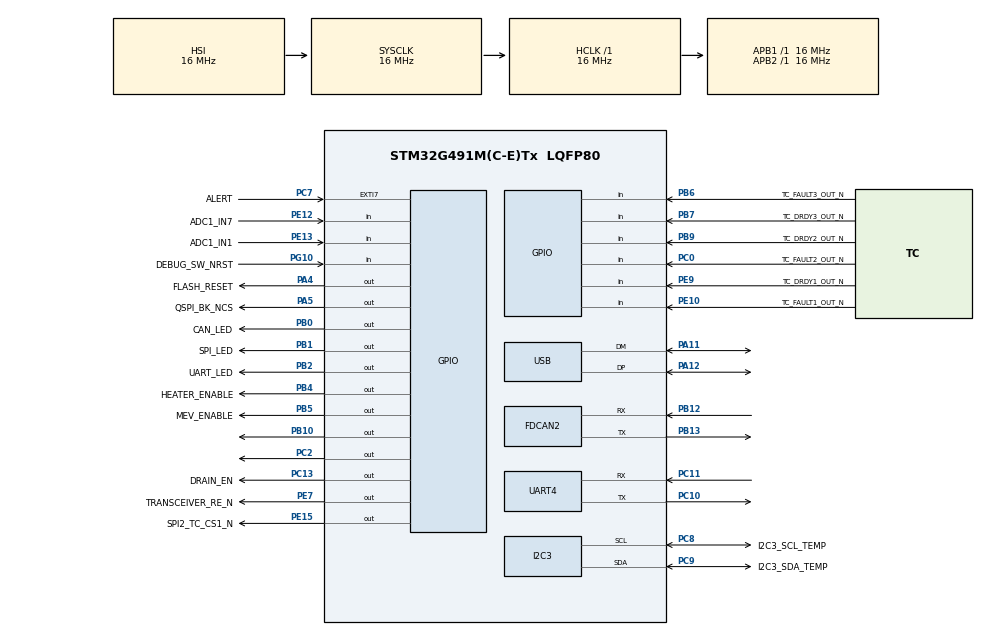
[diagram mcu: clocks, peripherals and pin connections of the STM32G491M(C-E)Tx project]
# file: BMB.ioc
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FDCAN2.CalculateBaudRateNominal=200000
FDCAN2.CalculateTimeBitNominal=5000
FDCAN2.CalculateTimeQuantumNominal=1000.0
FREERTOS.Tasks01=defaultTask,0,192,StartDefaultTask,Default,NULL,Dynamic,NULL,NULL
FREERTOS.configMINIMAL_STACK_SIZE=192
FREERTOS.configTOTAL_HEAP_SIZE=64000
FREERTOS.configUSE_NEWLIB_REENTRANT=1
FREERTOS.configUSE_TIMERS=1
Mcu.Family=STM32G4
Mcu.Name=STM32G491M(C-E)Tx
Mcu.Package=LQFP80
NVIC.EXTI9_5_IRQn=true\:5\:0\:false\:false\:true\:true\:true\:true\:true
NVIC.I2C3_EV_IRQn=true\:5\:0\:false\:false\:true\:true\:true\:true\:true
NVIC.PriorityGroup=NVIC_PRIORITYGROUP_4
NVIC.TIM2_IRQn=true\:15\:0\:false\:false\:true\:false\:false\:true\:true
NVIC.TimeBase=TIM2_IRQn
NVIC.TimeBaseIP=TIM2
NVIC.UART4_IRQn=true\:5\:0\:false\:false\:true\:true\:true\:true\:true
PA11.Mode=Device
PA11.Signal=USB_DM
PA12.Mode=Device
PA12.Signal=USB_DP
PA13.Mode=JTAG_4_pins
PA13.Signal=SYS_JTMS-SWDIO
PA14.Mode=JTAG_4_pins
PA14.Signal=SYS_JTCK-SWCLK
PA15.Mode=JTAG_4_pins
PA15.Signal=SYS_JTDI
PA4.GPIO_Label=FLASH_RESET
PA4.Signal=GPIO_Output
PA5.GPIO_Label=QSPI_BK_NCS
PA5.Signal=GPIO_Output
PB0.GPIO_Label=CAN_LED
PB0.Signal=GPIO_Output
PB1.GPIO_Label=SPI_LED
PB1.Signal=GPIO_Output
PB10.Signal=GPIO_Output
PB12.Mode=FDCAN_Activate
PB12.Signal=FDCAN2_RX
PB13.Mode=FDCAN_Activate
PB13.Signal=FDCAN2_TX
PB2.GPIO_Label=UART_LED
PB2.Signal=GPIO_Output
PB3.Mode=JTAG_4_pins
PB3.Signal=SYS_JTDO-SWO
PB4.GPIO_Label=HEATER_ENABLE
PB4.Signal=GPIO_Output
PB5.GPIO_Label=MEV_ENABLE
PB5.Signal=GPIO_Output
PB6.GPIO_Label=TC_FAULT3_OUT_N
PB6.Signal=GPIO_Input
PB7.GPIO_Label=TC_DRDY3_OUT_N
PB7.Signal=GPIO_Input
PB9.GPIO_Label=TC_DRDY2_OUT_N
PB9.Signal=GPIO_Input
PC0.GPIO_Label=TC_FAULT2_OUT_N
PC0.Signal=GPIO_Input
PC10.Mode=Asynchronous
PC10.Signal=UART4_TX
PC11.Mode=Asynchronous
PC11.Signal=UART4_RX
PC13.GPIO_Label=DRAIN_EN
PC13.Signal=GPIO_Output
PC2.Signal=GPIO_Output
PC7.GPIO_Label=ALERT
PC7.Signal=GPXTI7
PC8.GPIO_Label=I2C3_SCL_TEMP
PC8.Mode=I2C
PC8.Signal=I2C3_SCL
PC9.GPIO_Label=I2C3_SDA_TEMP
PC9.Mode=I2C
PC9.Signal=I2C3_SDA
PE10.GPIO_Label=TC_FAULT1_OUT_N
PE10.Signal=GPIO_Input
PE12.GPIO_Label=ADC1_IN7
PE12.Signal=GPIO_Input
PE13.GPIO_Label=ADC1_IN1
PE13.Signal=GPIO_Input
PE15.GPIO_Label=SPI2_TC_CS1_N
PE15.Signal=GPIO_Output
PE7.GPIO_Label=TRANSCEIVER_RE_N
PE7.Signal=GPIO_Output
PE9.GPIO_Label=TC_DRDY1_OUT_N
PE9.Signal=GPIO_Input
PF0-OSC_IN.Mode=HSE-External-Oscillator
PF0-OSC_IN.Signal=RCC_OSC_IN
PF1-OSC_OUT.Mode=HSE-External-Oscillator
PF1-OSC_OUT.Signal=RCC_OSC_OUT
PG10-NRST.GPIO_Label=DEBUG_SW_NRST
PG10-NRST.Signal=GPIO_Input
ProjectManager.HeapSize=0x200
ProjectManager.StackSize=0x400
ProjectManager.TargetToolchain=STM32CubeIDE
RCC.AHBFreq_Value=16000000
RCC.APB1Freq_Value=16000000
RCC.APB1TimFreq_Value=16000000
RCC.APB2Freq_Value=16000000
RCC.APB2TimFreq_Value=16000000
RCC.CortexFreq_Value=16000000
RCC.EXTERNAL_CLOCK_VALUE=12288000
RCC.HCLKFreq_Value=16000000
RCC.HSE_VALUE=8000000
RCC.HSI48_VALUE=48000000
RCC.HSI_VALUE=16000000
RCC.LSE_VALUE=32768
RCC.SYSCLKFreq_VALUE=16000000
RCC.USBFreq_Value=48000000
RCC.VCOOutputFreq_Value=128000000
VP_CRC_VS_CRC.Mode=CRC_Activate
VP_FREERTOS_VS_CMSIS_V1.Mode=CMSIS_V1
VP_SYS_VS_DBSignals.Mode=DisableDeadBatterySignals
VP_SYS_VS_tim2.Mode=TIM2
board=custom

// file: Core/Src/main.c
/* USER CODE BEGIN Header */
/**
  ******************************************************************************
  * @file           : main.c
  * @brief          : Main program body
  ******************************************************************************
  * @attention
  *
  * Copyright (c) 2026 STMicroelectronics.
  * All rights reserved.
  *
  * This software is licensed under terms that can be found in the LICENSE file
  * in the root directory of this software component.
  * If no LICENSE file comes with this software, it is provided AS-IS.
  *
  ******************************************************************************
  */
/* USER CODE END Header */
#include "main.h"
#include "cmsis_os.h"

/* USER CODE BEGIN Includes */

//#define USE_FULL_LL_DRIVER
/* USER CODE END Includes */

CRC_HandleTypeDef hcrc;

FDCAN_HandleTypeDef hfdcan2;

I2C_HandleTypeDef hi2c3;

UART_HandleTypeDef huart4;

PCD_HandleTypeDef hpcd_USB_FS;

osThreadId defaultTaskHandle;

void SystemClock_Config(void);
static void MX_GPIO_Init(void);
static void MX_CRC_Init(void);
static void MX_I2C3_Init(void);
static void MX_FDCAN2_Init(void);
static void MX_UART4_Init(void);
static void MX_USB_PCD_Init(void);
void StartDefaultTask(void const * argument);

/* USER CODE BEGIN PFP */
void BQ76942_NotifyAlertInterrupt(void);
void run_interface(void);

/* USER CODE END PFP */

int main(void)
{

  /* MCU Configuration--------------------------------------------------------*/

  /* Reset of all peripherals, Initializes the Flash interface and the Systick. */
  HAL_Init();

  /* Configure the system clock */
  SystemClock_Config();

  /* Initialize all configured peripherals */
  MX_GPIO_Init();
  MX_CRC_Init();
  MX_I2C3_Init();
  MX_FDCAN2_Init();
  MX_UART4_Init();
  MX_USB_PCD_Init();
  /* USER CODE BEGIN 2 */
  __enable_irq();

  run_interface();
  #if 0
  /* USER CODE END 2 */

  /* Create the thread(s) */
  /* definition and creation of defaultTask */
  osThreadDef(defaultTask, StartDefaultTask, osPriorityNormal, 0, 192);
  defaultTaskHandle = osThreadCreate(osThread(defaultTask), NULL);

  /* Start scheduler */
  osKernelStart();

  /* We should never get here as control is now taken by the scheduler */
  /* Infinite loop */
  while (1)
  {

    /* USER CODE BEGIN 3 */
  }

#endif
  /* USER CODE END 3 */
}

void SystemClock_Config(void)
{
  RCC_OscInitTypeDef RCC_OscInitStruct = {0};
  RCC_ClkInitTypeDef RCC_ClkInitStruct = {0};

  /** Configure the main internal regulator output voltage
  */
  HAL_PWREx_ControlVoltageScaling(PWR_REGULATOR_VOLTAGE_SCALE1);

  /** Initializes the RCC Oscillators according to the specified parameters
  * in the RCC_OscInitTypeDef structure.
  */
  RCC_OscInitStruct.OscillatorType = RCC_OSCILLATORTYPE_HSI|RCC_OSCILLATORTYPE_HSI48;
  RCC_OscInitStruct.HSIState = RCC_HSI_ON;
  RCC_OscInitStruct.HSICalibrationValue = RCC_HSICALIBRATION_DEFAULT;
  RCC_OscInitStruct.HSI48State = RCC_HSI48_ON;
  RCC_OscInitStruct.PLL.PLLState = RCC_PLL_NONE;
  if (HAL_RCC_OscConfig(&RCC_OscInitStruct) != HAL_OK)
  {
    Error_Handler();
  }

  /** Initializes the CPU, AHB and APB buses clocks
  */
  RCC_ClkInitStruct.ClockType = RCC_CLOCKTYPE_HCLK|RCC_CLOCKTYPE_SYSCLK
                              |RCC_CLOCKTYPE_PCLK1|RCC_CLOCKTYPE_PCLK2;
  RCC_ClkInitStruct.SYSCLKSource = RCC_SYSCLKSOURCE_HSI;
  RCC_ClkInitStruct.AHBCLKDivider = RCC_SYSCLK_DIV1;
  RCC_ClkInitStruct.APB1CLKDivider = RCC_HCLK_DIV1;
  RCC_ClkInitStruct.APB2CLKDivider = RCC_HCLK_DIV1;

  if (HAL_RCC_ClockConfig(&RCC_ClkInitStruct, FLASH_LATENCY_0) != HAL_OK)
  {
    Error_Handler();
  }
}

static void MX_CRC_Init(void)
{

  hcrc.Instance = CRC;
  hcrc.Init.DefaultPolynomialUse = DEFAULT_POLYNOMIAL_ENABLE;
  hcrc.Init.DefaultInitValueUse = DEFAULT_INIT_VALUE_ENABLE;
  hcrc.Init.InputDataInversionMode = CRC_INPUTDATA_INVERSION_NONE;
  hcrc.Init.OutputDataInversionMode = CRC_OUTPUTDATA_INVERSION_DISABLE;
  hcrc.InputDataFormat = CRC_INPUTDATA_FORMAT_BYTES;
  if (HAL_CRC_Init(&hcrc) != HAL_OK)
  {
    Error_Handler();
  }

}

static void MX_FDCAN2_Init(void)
{

  hfdcan2.Instance = FDCAN2;
  hfdcan2.Init.ClockDivider = FDCAN_CLOCK_DIV1;
  hfdcan2.Init.FrameFormat = FDCAN_FRAME_CLASSIC;
  hfdcan2.Init.Mode = FDCAN_MODE_NORMAL;
  hfdcan2.Init.AutoRetransmission = DISABLE;
  hfdcan2.Init.TransmitPause = DISABLE;
  hfdcan2.Init.ProtocolException = DISABLE;
  hfdcan2.Init.NominalPrescaler = 16;
  hfdcan2.Init.NominalSyncJumpWidth = 1;
  hfdcan2.Init.NominalTimeSeg1 = 2;
  hfdcan2.Init.NominalTimeSeg2 = 2;
  hfdcan2.Init.DataPrescaler = 1;
  hfdcan2.Init.DataSyncJumpWidth = 1;
  hfdcan2.Init.DataTimeSeg1 = 1;
  hfdcan2.Init.DataTimeSeg2 = 1;
  hfdcan2.Init.StdFiltersNbr = 0;
  hfdcan2.Init.ExtFiltersNbr = 0;
  hfdcan2.Init.TxFifoQueueMode = FDCAN_TX_FIFO_OPERATION;
  if (HAL_FDCAN_Init(&hfdcan2) != HAL_OK)
  {
    Error_Handler();
  }

}

static void MX_I2C3_Init(void)
{

  hi2c3.Instance = I2C3;
  hi2c3.Init.Timing = 0x00303D5B;
  hi2c3.Init.OwnAddress1 = 0;
  hi2c3.Init.AddressingMode = I2C_ADDRESSINGMODE_7BIT;
  hi2c3.Init.DualAddressMode = I2C_DUALADDRESS_DISABLE;
  hi2c3.Init.OwnAddress2 = 0;
  hi2c3.Init.OwnAddress2Masks = I2C_OA2_NOMASK;
  hi2c3.Init.GeneralCallMode = I2C_GENERALCALL_DISABLE;
  hi2c3.Init.NoStretchMode = I2C_NOSTRETCH_DISABLE;
  if (HAL_I2C_Init(&hi2c3) != HAL_OK)
  {
    Error_Handler();
  }

  /** Configure Analogue filter
  */
  if (HAL_I2CEx_ConfigAnalogFilter(&hi2c3, I2C_ANALOGFILTER_ENABLE) != HAL_OK)
  {
    Error_Handler();
  }

  /** Configure Digital filter
  */
  if (HAL_I2CEx_ConfigDigitalFilter(&hi2c3, 0) != HAL_OK)
  {
    Error_Handler();
  }

}

static void MX_UART4_Init(void)
{

  huart4.Instance = UART4;
  huart4.Init.BaudRate = 115200;
  huart4.Init.WordLength = UART_WORDLENGTH_8B;
  huart4.Init.StopBits = UART_STOPBITS_1;
  huart4.Init.Parity = UART_PARITY_NONE;
  huart4.Init.Mode = UART_MODE_TX_RX;
  huart4.Init.HwFlowCtl = UART_HWCONTROL_NONE;
  huart4.Init.OverSampling = UART_OVERSAMPLING_16;
  huart4.Init.OneBitSampling = UART_ONE_BIT_SAMPLE_DISABLE;
  huart4.Init.ClockPrescaler = UART_PRESCALER_DIV1;
  huart4.AdvancedInit.AdvFeatureInit = UART_ADVFEATURE_NO_INIT;
  if (HAL_UART_Init(&huart4) != HAL_OK)
  {
    Error_Handler();
  }
  if (HAL_UARTEx_SetTxFifoThreshold(&huart4, UART_TXFIFO_THRESHOLD_1_8) != HAL_OK)
  {
    Error_Handler();
  }
  if (HAL_UARTEx_SetRxFifoThreshold(&huart4, UART_RXFIFO_THRESHOLD_1_8) != HAL_OK)
  {
    Error_Handler();
  }
  if (HAL_UARTEx_DisableFifoMode(&huart4) != HAL_OK)
  {
    Error_Handler();
  }

}

static void MX_USB_PCD_Init(void)
{

  hpcd_USB_FS.Instance = USB;
  hpcd_USB_FS.Init.dev_endpoints = 8;
  hpcd_USB_FS.Init.speed = PCD_SPEED_FULL;
  hpcd_USB_FS.Init.phy_itface = PCD_PHY_EMBEDDED;
  hpcd_USB_FS.Init.Sof_enable = DISABLE;
  hpcd_USB_FS.Init.low_power_enable = DISABLE;
  hpcd_USB_FS.Init.lpm_enable = DISABLE;
  hpcd_USB_FS.Init.battery_charging_enable = DISABLE;
  if (HAL_PCD_Init(&hpcd_USB_FS) != HAL_OK)
  {
    Error_Handler();
  }

}

static void MX_GPIO_Init(void)
{
  GPIO_InitTypeDef GPIO_InitStruct = {0};

  /* GPIO Ports Clock Enable */
  __HAL_RCC_GPIOC_CLK_ENABLE();
  __HAL_RCC_GPIOF_CLK_ENABLE();
  __HAL_RCC_GPIOG_CLK_ENABLE();
  __HAL_RCC_GPIOA_CLK_ENABLE();
  __HAL_RCC_GPIOB_CLK_ENABLE();
  __HAL_RCC_GPIOE_CLK_ENABLE();

  /*Configure GPIO pin Output Level */
  HAL_GPIO_WritePin(GPIOC, DRAIN_EN_Pin|GPIO_PIN_2, GPIO_PIN_RESET);

  /*Configure GPIO pin Output Level */
  HAL_GPIO_WritePin(GPIOA, FLASH_RESET_Pin|QSPI_BK_NCS_Pin, GPIO_PIN_RESET);

  /*Configure GPIO pin Output Level */
  HAL_GPIO_WritePin(GPIOB, CAN_LED_Pin|SPI_LED_Pin|UART_LED_Pin|GPIO_PIN_10
                          |HEATER_ENABLE_Pin|MEV_ENABLE_Pin, GPIO_PIN_RESET);

  /*Configure GPIO pin Output Level */
  HAL_GPIO_WritePin(GPIOE, TRANSCEIVER_RE_N_Pin|SPI2_TC_CS1_N_Pin, GPIO_PIN_RESET);

  /*Configure GPIO pins : DRAIN_EN_Pin PC2 */
  GPIO_InitStruct.Pin = DRAIN_EN_Pin|GPIO_PIN_2;
  GPIO_InitStruct.Mode = GPIO_MODE_OUTPUT_PP;
  GPIO_InitStruct.Pull = GPIO_NOPULL;
  GPIO_InitStruct.Speed = GPIO_SPEED_FREQ_LOW;
  HAL_GPIO_Init(GPIOC, &GPIO_InitStruct);

  /*Configure GPIO pin : DEBUG_SW_NRST_Pin */
  GPIO_InitStruct.Pin = DEBUG_SW_NRST_Pin;
  GPIO_InitStruct.Mode = GPIO_MODE_INPUT;
  GPIO_InitStruct.Pull = GPIO_NOPULL;
  HAL_GPIO_Init(DEBUG_SW_NRST_GPIO_Port, &GPIO_InitStruct);

  /*Configure GPIO pin : TC_FAULT2_OUT_N_Pin */
  GPIO_InitStruct.Pin = TC_FAULT2_OUT_N_Pin;
  GPIO_InitStruct.Mode = GPIO_MODE_INPUT;
  GPIO_InitStruct.Pull = GPIO_NOPULL;
  HAL_GPIO_Init(TC_FAULT2_OUT_N_GPIO_Port, &GPIO_InitStruct);

  /*Configure GPIO pins : FLASH_RESET_Pin QSPI_BK_NCS_Pin */
  GPIO_InitStruct.Pin = FLASH_RESET_Pin|QSPI_BK_NCS_Pin;
  GPIO_InitStruct.Mode = GPIO_MODE_OUTPUT_PP;
  GPIO_InitStruct.Pull = GPIO_NOPULL;
  GPIO_InitStruct.Speed = GPIO_SPEED_FREQ_LOW;
  HAL_GPIO_Init(GPIOA, &GPIO_InitStruct);

  /*Configure GPIO pins : CAN_LED_Pin SPI_LED_Pin UART_LED_Pin PB10
                           HEATER_ENABLE_Pin MEV_ENABLE_Pin */
  GPIO_InitStruct.Pin = CAN_LED_Pin|SPI_LED_Pin|UART_LED_Pin|GPIO_PIN_10
                          |HEATER_ENABLE_Pin|MEV_ENABLE_Pin;
  GPIO_InitStruct.Mode = GPIO_MODE_OUTPUT_PP;
  GPIO_InitStruct.Pull = GPIO_NOPULL;
  GPIO_InitStruct.Speed = GPIO_SPEED_FREQ_LOW;
  HAL_GPIO_Init(GPIOB, &GPIO_InitStruct);

  /*Configure GPIO pins : TRANSCEIVER_RE_N_Pin SPI2_TC_CS1_N_Pin */
  GPIO_InitStruct.Pin = TRANSCEIVER_RE_N_Pin|SPI2_TC_CS1_N_Pin;
  GPIO_InitStruct.Mode = GPIO_MODE_OUTPUT_PP;
  GPIO_InitStruct.Pull = GPIO_NOPULL;
  GPIO_InitStruct.Speed = GPIO_SPEED_FREQ_LOW;
  HAL_GPIO_Init(GPIOE, &GPIO_InitStruct);

  /*Configure GPIO pins : TC_DRDY1_OUT_N_Pin TC_FAULT1_OUT_N_Pin ADC1_IN7_Pin ADC1_IN1_Pin */
  GPIO_InitStruct.Pin = TC_DRDY1_OUT_N_Pin|TC_FAULT1_OUT_N_Pin|ADC1_IN7_Pin|ADC1_IN1_Pin;
  GPIO_InitStruct.Mode = GPIO_MODE_INPUT;
  GPIO_InitStruct.Pull = GPIO_NOPULL;
  HAL_GPIO_Init(GPIOE, &GPIO_InitStruct);

  /*Configure GPIO pin : ALERT_Pin */
  GPIO_InitStruct.Pin = ALERT_Pin;
  GPIO_InitStruct.Mode = GPIO_MODE_IT_RISING;
  GPIO_InitStruct.Pull = GPIO_NOPULL;
  HAL_GPIO_Init(ALERT_GPIO_Port, &GPIO_InitStruct);

  /*Configure GPIO pins : TC_FAULT3_OUT_N_Pin TC_DRDY3_OUT_N_Pin TC_DRDY2_OUT_N_Pin */
  GPIO_InitStruct.Pin = TC_FAULT3_OUT_N_Pin|TC_DRDY3_OUT_N_Pin|TC_DRDY2_OUT_N_Pin;
  GPIO_InitStruct.Mode = GPIO_MODE_INPUT;
  GPIO_InitStruct.Pull = GPIO_NOPULL;
  HAL_GPIO_Init(GPIOB, &GPIO_InitStruct);

  /* EXTI interrupt init*/
  HAL_NVIC_SetPriority(EXTI9_5_IRQn, 5, 0);
  HAL_NVIC_EnableIRQ(EXTI9_5_IRQn);

}

/* USER CODE BEGIN 4 */
void HAL_GPIO_EXTI_Callback(uint16_t GPIO_Pin)
{
  if (GPIO_Pin == ALERT_Pin)
  {
    BQ76942_NotifyAlertInterrupt();
  }
}

/* USER CODE END 4 */

void StartDefaultTask(void const * argument)
{
  for(;;)
  {
    osDelay(1);
  }
}

void HAL_TIM_PeriodElapsedCallback(TIM_HandleTypeDef *htim)
{
  if (htim->Instance == TIM2) {
    HAL_IncTick();
  }
}

void Error_Handler(void)
{
  __disable_irq();
  while (1)
  {
  }
}
